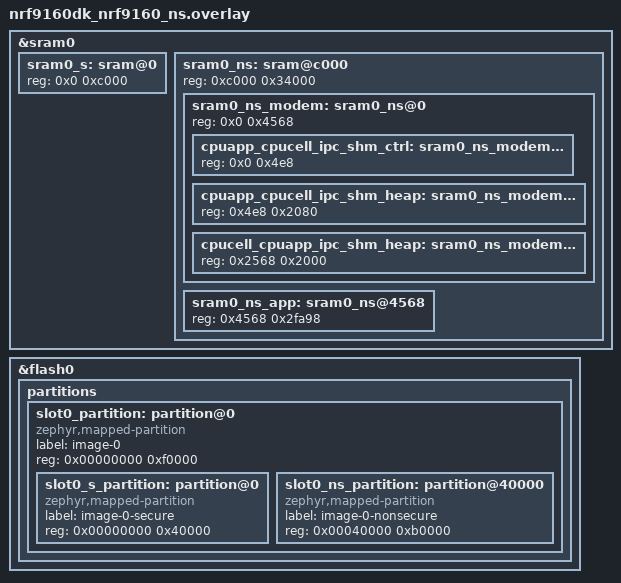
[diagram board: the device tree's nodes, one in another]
/*
 * Copyright (c) 2026 Nordic Semiconductor ASA
 *
 * SPDX-License-Identifier: LicenseRef-Nordic-5-Clause
 */

/* Customise both TFM and APP partitions so both will fit. */
/delete-node/ &sram0_s;
/delete-node/ &sram0_ns;

&sram0 {
	/*
	 * 0x2000_0000  Secure RAM                      (   48 kB)
	 * 0x2000_c000  Non-secure RAM area             (  208 kB)
	 *   0x2000_c000  Modem shared area             ( 17768 B)
	 *     0x2000_c000  control                     (  1256 B)
	 *     0x2000_c4e8  app -> cell                 (  8320 B)
	 *     0x2000_e568  cell -> app                 (    8 kB)
	 *   0x2001_0568  Application RAM               (195224 B)
	 */
	sram0_s: sram@0 {
		reg = <0x0 0xc000>;
	};

	sram0_ns: sram@c000 {
		reg = <0xc000 0x34000>;
		#address-cells = <1>;
		#size-cells = <1>;
		ranges = <0x0 0xc000 0x34000>;

		/* Must be in first 128 kB of RAM. */
		sram0_ns_modem: sram0_ns@0 {
			/* Modem (shared) memory */
			reg = <0x0 0x4568>;
			#address-cells = <1>;
			#size-cells = <1>;
			ranges = <0x0 0x0 0x4568>;

			cpuapp_cpucell_ipc_shm_ctrl: sram0_ns_modem@0 {
				/* Modem IPC control */
				reg = <0x0 0x4e8>;
			};

			cpuapp_cpucell_ipc_shm_heap: sram0_ns_modem@4e8 {
				/* Modem IPC transmit */
				reg = <0x4e8 0x2080>;
			};

			cpucell_cpuapp_ipc_shm_heap: sram0_ns_modem@2568 {
				/* Modem IPC receive */
				reg = <0x2568 0x2000>;
			};
		};

		sram0_ns_app: sram0_ns@4568 {
			/* Non-Secure application memory */
			reg = <0x4568 0x2fa98>;
		};
	};
};

/delete-node/ &boot_partition;
/delete-node/ &slot0_partition;
/delete-node/ &slot1_partition;

&flash0 {
	/*
	 * 0x0000_0000  Primary area			(960 kB)
	 *   0x0000_0000  Primary secure image		(256 kB)
	 *   0x0004_0000  Primary non-secure image	(704 kB)
	 *
	 * Unchanged:
	 * 0x000f_0000 Protected Storage Area           ( 16 KB)
	 * 0x000f_4000 Internal Trusted Storage Area    (  8 KB)
	 * 0x000f_6000 OTP / NV counters area           (  8 KB)
	 * 0x000f_8000  Settings storage		( 32 kB)
	 */
	partitions {
		ranges;
		#address-cells = <1>;
		#size-cells = <1>;

		slot0_partition: partition@0 {
			compatible = "zephyr,mapped-partition";
			label = "image-0";
			reg = <0x00000000 0xf0000>;
			ranges = <0x0 0x00000000 0xf0000>;
			#address-cells = <1>;
			#size-cells = <1>;

			slot0_s_partition: partition@0 {
				compatible = "zephyr,mapped-partition";
				label = "image-0-secure";
				reg = <0x00000000 0x40000>;
			};

			slot0_ns_partition: partition@40000 {
				compatible = "zephyr,mapped-partition";
				label = "image-0-nonsecure";
				reg = <0x00040000 0xb0000>;
			};
		};
	};
};
